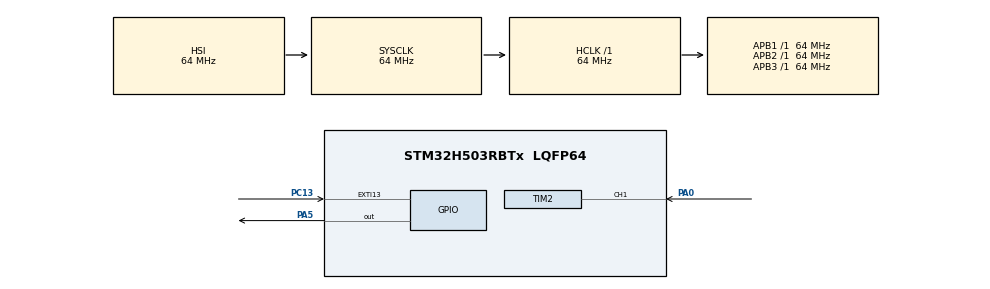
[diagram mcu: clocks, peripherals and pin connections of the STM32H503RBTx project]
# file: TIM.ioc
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BOOTPATH.BootPathName=LEGACY
BOOTPATH.UserSelectedBootPath=LEGACY
CORTEX_M33_NS.MPU_Control=__NULL
Mcu.Family=STM32H5
Mcu.Name=STM32H503RBTx
Mcu.Package=LQFP64
NUCLEO-H503RB.BUTTON=2
NUCLEO-H503RB.LD2=true
NUCLEO-H503RB.VCP=true
NVIC.PriorityGroup=NVIC_PRIORITYGROUP_4
NVIC.TIM6_IRQn=true\:15\:0\:false\:false\:true\:false\:true\:true
NVIC.TIM7_IRQn=true\:0\:0\:false\:false\:true\:true\:true\:true
NVIC.TimeBase=TIM6_IRQn
NVIC.TimeBaseIP=TIM6
PA0.Signal=S_TIM2_CH1
PA13(JTMS/SWDIO).Mode=Trace_Asynchronous_SW
PA13(JTMS/SWDIO).Signal=DEBUG_JTMS-SWDIO
PA14(JTCK/SWCLK).Mode=Trace_Asynchronous_SW
PA14(JTCK/SWCLK).Signal=DEBUG_JTCK-SWCLK
PA3.Signal=USART3_RX
PA4.Signal=USART3_TX
PA5.Signal=GPIO_Output
PB3(JTDO/TRACESWO).Mode=Trace_Asynchronous_SW
PB3(JTDO/TRACESWO).Signal=DEBUG_JTDO-SWO
PC13.Signal=GPXTI13
ProjectManager.HeapSize=0x200
ProjectManager.StackSize=0x400
ProjectManager.TargetToolchain=STM32CubeIDE
RCC.ADCFreq_Value=64000000
RCC.AHBFreq_Value=64000000
RCC.APB1Freq_Value=64000000
RCC.APB1TimFreq_Value=64000000
RCC.APB2Freq_Value=64000000
RCC.APB2TimFreq_Value=64000000
RCC.APB3Freq_Value=64000000
RCC.CSI_VALUE=4000000
RCC.CortexFreq_Value=64000000
RCC.EPOD_VALUE=4000000
RCC.HCLKFreq_Value=64000000
RCC.HSE_VALUE=24000000
RCC.HSI48_VALUE=48000000
RCC.HSIDiv=RCC_HSI_DIV1
RCC.HSI_VALUE=64000000
RCC.LSE_VALUE=32768
RCC.LSIRC_VALUE=32000
RCC.PLLN=32
RCC.SYSCLKFreq_VALUE=64000000
RCC.USBFreq_Value=48000000
RCC.VCOOutputFreq_Value=128000000
SH.S_TIM2_CH1.0=TIM2_CH1,Input_Capture1_from_TI1
TIM2.Channel-Input_Capture1_from_TI1=TIM_CHANNEL_1
TIM2.ICPolarity_CH1=TIM_INPUTCHANNELPOLARITY_BOTHEDGE
TIM7.PeriodNoDither=1000-1
TIM7.Prescaler=128-1
VP_BOOTPATH_VS_BOOTPATH.Mode=BP_Activate
VP_CORTEX_M33_NS_VS_Hclk.Mode=Hclk_Mode
VP_MEMORYMAP_VS_MEMORYMAP.Mode=CurAppReg
VP_NUCLEO-H503RB_VS_BSP_COMMON.Mode=COMMON
VP_PWR_VS_DBSignals.Mode=DisableDeadBatterySignals
VP_PWR_VS_LPOM.Mode=PowerOptimisation
VP_PWR_VS_SECSignals.Mode=Security/Privilege
VP_SYS_VS_tim6.Mode=TIM6
VP_TIM7_VS_ClockSourceINT.Mode=Enable_Timer
board=NUCLEO-H503RB

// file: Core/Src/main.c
/* USER CODE BEGIN Header */
/**
  ******************************************************************************
  * @file           : main.c
  * @brief          : Main program body
  ******************************************************************************
  * @attention
  *
  * Copyright (c) 2025 STMicroelectronics.
  * All rights reserved.
  *
  * This software is licensed under terms that can be found in the LICENSE file
  * in the root directory of this software component.
  * If no LICENSE file comes with this software, it is provided AS-IS.
  *
  ******************************************************************************
  */
/* USER CODE END Header */
#include "main.h"
#include "tim.h"
#include "gpio.h"

COM_InitTypeDef BspCOMInit;

void SystemClock_Config(void);

/* USER CODE BEGIN 0 */
void HAL_TIM7_PeriodElapsedCallback(TIM_HandleTypeDef *htim)
{

}

void HAL_TIM2_IC_CaptureCallback(TIM_HandleTypeDef *htim)
{
	static capture_count = 0;
	static capture[2];
	//capture
	capture[capture_count] = __HAL_TIM_GET_COMPARE(&htim2, TIM_CHANNEL_1);

	capture_count += 1;

	if(capture_count == 2)
	{
		//process

		capture_count = 0;
	}
}
/* USER CODE END 0 */

int main(void)
{

  /* MCU Configuration--------------------------------------------------------*/

  /* Reset of all peripherals, Initializes the Flash interface and the Systick. */
  HAL_Init();

  /* Configure the system clock */
  SystemClock_Config();

  /* Initialize all configured peripherals */
  MX_GPIO_Init();
  MX_TIM7_Init();
  MX_TIM2_Init();
  /* USER CODE BEGIN 2 */
  HAL_TIM_RegisterCallback(&htim7,  HAL_TIM_PERIOD_ELAPSED_CB_ID, HAL_TIM7_PeriodElapsedCallback);

  HAL_TIM_RegisterCallback(&htim2, HAL_TIM_IC_CAPTURE_CB_ID , HAL_TIM2_IC_CaptureCallback);
  HAL_TIM_Base_Start_IT(&htim7);
  /* USER CODE END 2 */

  /* Initialize led */
  BSP_LED_Init(LED_GREEN);

  /* Initialize User push-button without interrupt mode. */
  BSP_PB_Init(BUTTON_USER, BUTTON_MODE_GPIO);

  /* Initialize COM1 port (115200, 8 bits (7-bit data + 1 stop bit), no parity */
  BspCOMInit.BaudRate   = 115200;
  BspCOMInit.WordLength = COM_WORDLENGTH_8B;
  BspCOMInit.StopBits   = COM_STOPBITS_1;
  BspCOMInit.Parity     = COM_PARITY_NONE;
  BspCOMInit.HwFlowCtl  = COM_HWCONTROL_NONE;
  if (BSP_COM_Init(COM1, &BspCOMInit) != BSP_ERROR_NONE)
  {
    Error_Handler();
  }

  /* Infinite loop */
  while (1)
  {

  }
}

void SystemClock_Config(void)
{
  RCC_OscInitTypeDef RCC_OscInitStruct = {0};
  RCC_ClkInitTypeDef RCC_ClkInitStruct = {0};

  /** Configure the main internal regulator output voltage
  */
  __HAL_PWR_VOLTAGESCALING_CONFIG(PWR_REGULATOR_VOLTAGE_SCALE3);

  while(!__HAL_PWR_GET_FLAG(PWR_FLAG_VOSRDY)) {}

  /** Initializes the RCC Oscillators according to the specified parameters
  * in the RCC_OscInitTypeDef structure.
  */
  RCC_OscInitStruct.OscillatorType = RCC_OSCILLATORTYPE_HSI;
  RCC_OscInitStruct.HSIState = RCC_HSI_ON;
  RCC_OscInitStruct.HSIDiv = RCC_HSI_DIV1;
  RCC_OscInitStruct.HSICalibrationValue = RCC_HSICALIBRATION_DEFAULT;
  RCC_OscInitStruct.PLL.PLLState = RCC_PLL_NONE;
  if (HAL_RCC_OscConfig(&RCC_OscInitStruct) != HAL_OK)
  {
    Error_Handler();
  }

  /** Initializes the CPU, AHB and APB buses clocks
  */
  RCC_ClkInitStruct.ClockType = RCC_CLOCKTYPE_HCLK|RCC_CLOCKTYPE_SYSCLK
                              |RCC_CLOCKTYPE_PCLK1|RCC_CLOCKTYPE_PCLK2
                              |RCC_CLOCKTYPE_PCLK3;
  RCC_ClkInitStruct.SYSCLKSource = RCC_SYSCLKSOURCE_HSI;
  RCC_ClkInitStruct.AHBCLKDivider = RCC_SYSCLK_DIV1;
  RCC_ClkInitStruct.APB1CLKDivider = RCC_HCLK_DIV1;
  RCC_ClkInitStruct.APB2CLKDivider = RCC_HCLK_DIV1;
  RCC_ClkInitStruct.APB3CLKDivider = RCC_HCLK_DIV1;

  if (HAL_RCC_ClockConfig(&RCC_ClkInitStruct, FLASH_LATENCY_3) != HAL_OK)
  {
    Error_Handler();
  }

  /** Configure the programming delay
  */
  __HAL_FLASH_SET_PROGRAM_DELAY(FLASH_PROGRAMMING_DELAY_1);
}

void HAL_TIM_PeriodElapsedCallback(TIM_HandleTypeDef *htim)
{
  if (htim->Instance == TIM6)
  {
    HAL_IncTick();
  }
}

void Error_Handler(void)
{
  __disable_irq();
  while (1)
  {
  }
}
